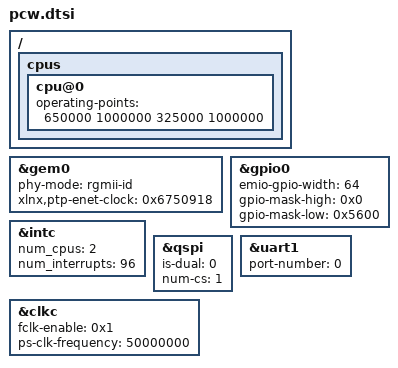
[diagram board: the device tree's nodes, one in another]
/*
 * CAUTION: This file is automatically generated by Xilinx.
 * Version: XSCT 2018.3
 * Today is: Thu Jun  3 12:51:47 2021
 */


/ {
	cpus {
		cpu@0 {
			operating-points = <650000 1000000 325000 1000000>;
		};
	};
};
&gem0 {
	phy-mode = "rgmii-id";
	status = "okay";
	xlnx,ptp-enet-clock = <0x6750918>;
};
&gpio0 {
	emio-gpio-width = <64>;
	gpio-mask-high = <0x0>;
	gpio-mask-low = <0x5600>;
};
&intc {
	num_cpus = <2>;
	num_interrupts = <96>;
};
&qspi {
	is-dual = <0>;
	num-cs = <1>;
	status = "okay";
};
&uart1 {
	device_type = "serial";
	port-number = <0>;
	status = "okay";
};
&clkc {
	fclk-enable = <0x1>;
	ps-clk-frequency = <50000000>;
};
